VERSION ""

NS_ :

BS_:

BU_: MaxxECU Diagnostic BCM
VAL_TABLE_ YesNo 1 "Yes" 0 "No" ;
VAL_TABLE_ Alarm_Status 8 "Error 5" 7 "Error 4" 6 "Error 3" 5 "Error 2" 4 "Error 1" 3 "Disabled" 2 "Unarmed" 1 "Armed" 0 "Unknown" ;
VAL_TABLE_ Door_Status 2 "Closed" 1 "Open" 0 "Unknown" ;
VAL_TABLE_ Window_Status 4 "Moving Down" 3 "Moving Up" 2 "Open" 1 "Closed" 0 "Unknown" ;
VAL_TABLE_ Seat_Heater_Level 3 "Level 3" 2 "Level 2" 1 "Level 1" 0 "Off" ;
VAL_TABLE_ Wiper_Speed 5 "Auto" 4 "Speed 3" 3 "Speed 2" 2 "Speed 1" 1 "Interval" 0 "Off" ;
VAL_TABLE_ OnOff 1 "On" 0 "Off" ;

BO_ 1312 MSG_0x520: 2 Vector__XXX
 SG_ EngineSpeed_MaxxECU : 0|16@1+ (1,0) [0|65535] "rpm" Vector__XXX

BO_ 368 Electrical_Status: 8 Vector__XXX

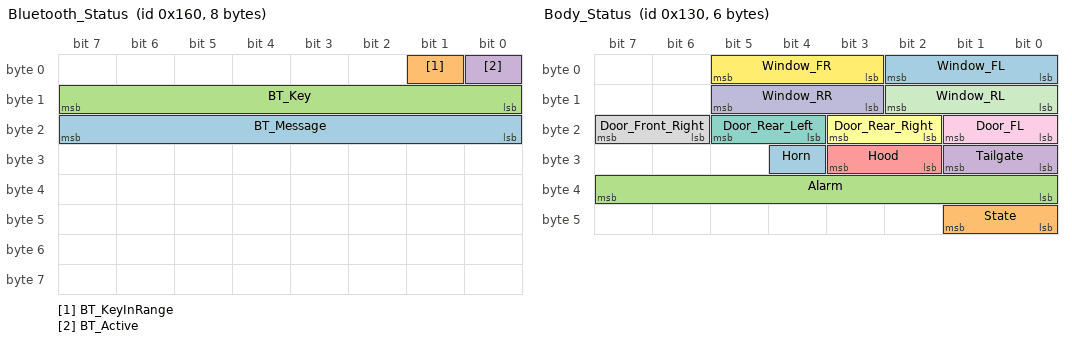
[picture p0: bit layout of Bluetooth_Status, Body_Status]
BO_ 352 Bluetooth_Status: 8 Vector__XXX
 SG_ BT_Message : 16|8@1+ (1,0) [0|255] "" Vector__XXX
 SG_ BT_KeyInRange : 1|1@1+ (1,0) [0|0] "" Vector__XXX
 SG_ BT_Key : 8|8@1+ (1,0) [0|255] "" Vector__XXX
 SG_ BT_Active : 0|1@1+ (1,0) [0|255] "" Vector__XXX

BO_ 336 Switch_Status: 8 Vector__XXX

BO_ 320 Chassi_Status: 8 Vector__XXX

BO_ 304 Body_Status: 6 Vector__XXX
 SG_ Horn : 28|1@1+ (1,0) [0|1] "" Vector__XXX
 SG_ State : 40|2@1+ (1,0) [0|0] "" Vector__XXX
 SG_ Alarm : 32|8@1+ (1,0) [0|15] "" Vector__XXX
 SG_ Tailgate : 24|2@1+ (1,0) [0|3] "" Vector__XXX
 SG_ Hood : 26|2@1+ (1,0) [0|3] "" Vector__XXX
 SG_ Door_Rear_Right : 18|2@1+ (1,0) [0|3] "" Vector__XXX
 SG_ Door_Rear_Left : 20|2@1+ (1,0) [0|3] "" Vector__XXX
 SG_ Door_Front_Right : 22|2@1+ (1,0) [0|3] "" Vector__XXX
 SG_ Door_FL : 16|2@1+ (1,0) [0|3] "" Vector__XXX
 SG_ Window_RR : 11|3@1+ (1,0) [0|7] "" Vector__XXX
 SG_ Window_RL : 8|3@1+ (1,0) [0|7] "" Vector__XXX
 SG_ Window_FR : 3|3@1+ (1,0) [0|7] "" Vector__XXX
 SG_ Window_FL : 0|3@1+ (1,0) [0|7] "" Vector__XXX

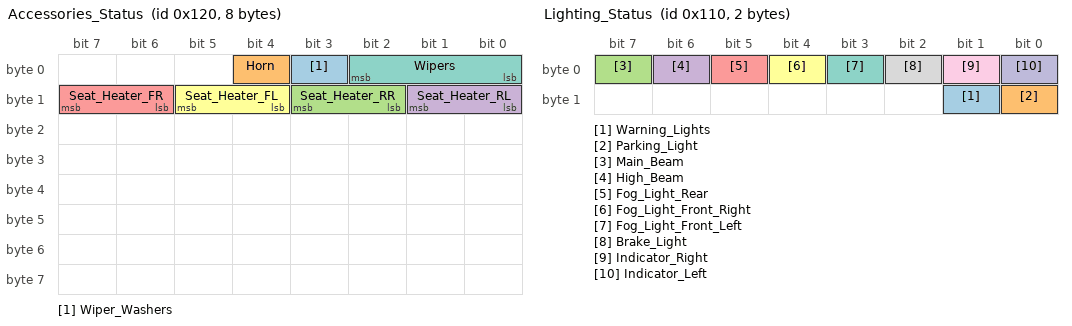
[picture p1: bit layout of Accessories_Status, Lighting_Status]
BO_ 288 Accessories_Status: 8 Vector__XXX
 SG_ Wiper_Washers : 3|1@1+ (1,0) [0|1] "" Vector__XXX
 SG_ Horn : 4|1@1+ (1,0) [0|1] "" Vector__XXX
 SG_ Seat_Heater_RR : 10|2@1+ (1,0) [0|3] "" Vector__XXX
 SG_ Seat_Heater_RL : 8|2@1+ (1,0) [0|3] "" Vector__XXX
 SG_ Seat_Heater_FR : 14|2@1+ (1,0) [0|3] "" Vector__XXX
 SG_ Seat_Heater_FL : 12|2@1+ (1,0) [0|3] "" Vector__XXX
 SG_ Wipers : 0|3@1+ (1,0) [0|7] "" Vector__XXX

BO_ 272 Lighting_Status: 2 BCM
 SG_ Warning_Lights : 9|1@1+ (1,0) [0|1] "" Vector__XXX
 SG_ Parking_Light : 8|1@1+ (1,0) [0|1] "" Vector__XXX
 SG_ Main_Beam : 7|1@1+ (1,0) [0|1] "" Vector__XXX
 SG_ High_Beam : 6|1@1+ (1,0) [0|1] "" Vector__XXX
 SG_ Fog_Light_Rear : 5|1@1+ (1,0) [0|1] "" Vector__XXX
 SG_ Fog_Light_Front_Right : 4|1@1+ (1,0) [0|1] "" Vector__XXX
 SG_ Fog_Light_Front_Left : 3|1@1+ (1,0) [0|1] "" Vector__XXX
 SG_ Brake_Light : 2|1@1+ (1,0) [0|1] "" Vector__XXX
 SG_ Indicator_Right : 1|1@1+ (1,0) [0|1] "" Vector__XXX
 SG_ Indicator_Left : 0|1@1+ (1,0) [0|1] "" Vector__XXX

VAL_ 352 BT_Active 1 "Yes" 0 "No" ;
VAL_ 304 Horn 1 "On" 0 "Off" ;
VAL_ 304 Alarm 8 "Error 5" 7 "Error 4" 6 "Error 3" 5 "Error 2" 4 "Error 1" 3 "Disabled" 2 "Unarmed" 1 "Armed" 0 "Unknown" ;
VAL_ 304 Tailgate 2 "Closed" 1 "Open" 0 "Unknown" ;
VAL_ 304 Hood 2 "Closed" 1 "Open" 0 "Unknown" ;
VAL_ 304 Door_Rear_Right 2 "Closed" 1 "Open" 0 "Unknown" ;
VAL_ 304 Door_Rear_Left 2 "Closed" 1 "Open" 0 "Unknown" ;
VAL_ 304 Door_Front_Right 2 "Closed" 1 "Open" 0 "Unknown" ;
VAL_ 304 Door_FL 2 "Closed" 1 "Open" 0 "Unknown" ;
VAL_ 304 Window_RR 4 "Moving Down" 3 "Moving Up" 2 "Open" 1 "Closed" 0 "Unknown" ;
VAL_ 304 Window_RL 4 "Moving Down" 3 "Moving Up" 2 "Open" 1 "Closed" 0 "Unknown" ;
VAL_ 304 Window_FR 4 "Moving Down" 3 "Moving Up" 2 "Open" 1 "Closed" 0 "Unknown" ;
VAL_ 304 Window_FL 4 "Moving Down" 3 "Moving Up" 2 "Open" 1 "Closed" 0 "Unknown" ;
VAL_ 288 Wiper_Washers 1 "On" 0 "Off" ;
VAL_ 288 Horn 1 "On" 0 "Off" ;
VAL_ 288 Seat_Heater_RR 3 "Level 3" 2 "Level 2" 1 "Level 1" 0 "Off" ;
VAL_ 288 Seat_Heater_RL 3 "Level 3" 2 "Level 2" 1 "Level 1" 0 "Off" ;
VAL_ 288 Seat_Heater_FR 3 "Level 3" 2 "Level 2" 1 "Level 1" 0 "Off" ;
VAL_ 288 Seat_Heater_FL 3 "Level 3" 2 "Level 2" 1 "Level 1" 0 "Off" ;
VAL_ 288 Wipers 5 "Auto" 4 "Speed 3" 3 "Speed 2" 2 "Speed 1" 1 "Interval" 0 "Off" ;
VAL_ 272 Warning_Lights 1 "On" 0 "Off" ;
VAL_ 272 Parking_Light 1 "On" 0 "Off" ;
VAL_ 272 Main_Beam 1 "On" 0 "Off" ;
VAL_ 272 High_Beam 1 "On" 0 "Off" ;
VAL_ 272 Fog_Light_Rear 1 "On" 0 "Off" ;
VAL_ 272 Fog_Light_Front_Right 1 "On" 0 "Off" ;
VAL_ 272 Fog_Light_Front_Left 1 "On" 0 "Off" ;
VAL_ 272 Brake_Light 1 "On" 0 "Off" ;
VAL_ 272 Indicator_Right 1 "On" 0 "Off" ;
VAL_ 272 Indicator_Left 1 "On" 0 "Off" ;
